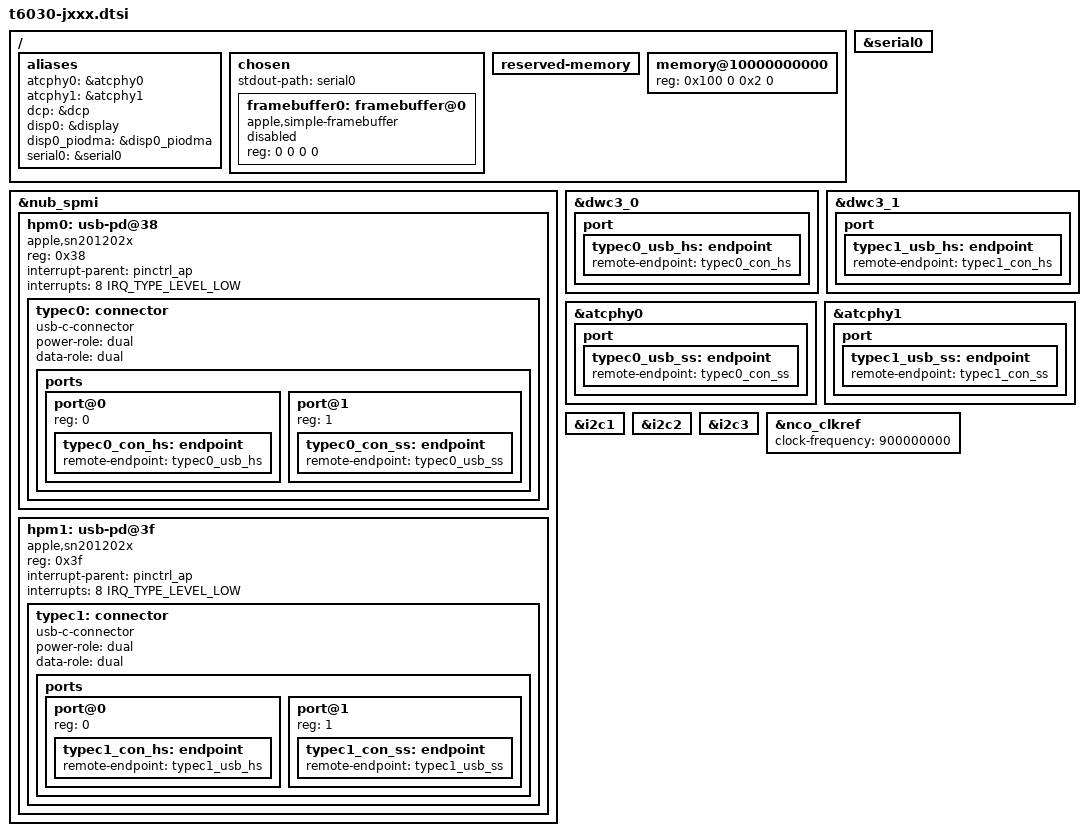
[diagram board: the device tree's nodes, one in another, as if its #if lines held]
// SPDX-License-Identifier: GPL-2.0+ OR MIT
/*
 * Apple M3 MacBook Pro (M3, 2023)
 *
 * This file contains parts common to all Apple M3 devices using the t6030 SoC.
 *
 * target-type: J514 ,..
 *
 * Copyright The Asahi Linux Contributors
 */

/ {
	aliases {
#ifdef T6030_BRINGUP_UNKNOWN
		atcphy0 = &atcphy0;
		atcphy1 = &atcphy1;
		dcp = &dcp;
		disp0 = &display;
		disp0_piodma = &disp0_piodma;
#endif // T6030_BRINGUP_UNKNOWN
		serial0 = &serial0;
	};

	chosen {
		#address-cells = <2>;
		#size-cells = <2>;
		ranges;

		stdout-path = "serial0";

		framebuffer0: framebuffer@0 {
			compatible = "apple,simple-framebuffer", "simple-framebuffer";
			reg = <0 0 0 0>; /* To be filled by loader */
			//power-domains = <&ps_disp_cpu>;
			/* Format properties will be added by loader */
			status = "disabled";
		};
	};

	reserved-memory {
		#address-cells = <2>;
		#size-cells = <2>;
		ranges;
		/* To be filled by loader */
	};

	memory@10000000000 {
		device_type = "memory";
		reg = <0x100 0 0x2 0>; /* To be filled by loader */
	};

};

&serial0 {
	status = "okay";
};

#ifdef T6030_BRINGUP_UNKNOWN
//left-back
&nub_spmi {
	status = "okay";

	hpm0: usb-pd@38 {
		compatible = "apple,sn201202x";
		reg = <0x38>;
		interrupt-parent = <&pinctrl_ap>;
		interrupts = <8 IRQ_TYPE_LEVEL_LOW>;
		interrupt-names = "irq";

		typec0: connector {
			compatible = "usb-c-connector";
			power-role = "dual";
			data-role = "dual";

			ports {
				#address-cells = <1>;
				#size-cells = <0>;
				port@0 {
					reg = <0>;
					typec0_con_hs: endpoint {
						remote-endpoint = <&typec0_usb_hs>;
					};
				};
				port@1 {
					reg = <1>;
					typec0_con_ss: endpoint {
						remote-endpoint = <&typec0_usb_ss>;
					};
				};
			};
		};
	};
//left-front
	hpm1: usb-pd@3f {
		compatible = "apple,sn201202x";
		reg = <0x3f>;
		interrupt-parent = <&pinctrl_ap>;
		interrupts = <8 IRQ_TYPE_LEVEL_LOW>;
		interrupt-names = "irq";

		typec1: connector {
			compatible = "usb-c-connector";
			power-role = "dual";
			data-role = "dual";

			ports {
				#address-cells = <1>;
				#size-cells = <0>;
				port@0 {
					reg = <0>;
					typec1_con_hs: endpoint {
						remote-endpoint = <&typec1_usb_hs>;
					};
				};
				port@1 {
					reg = <1>;
					typec1_con_ss: endpoint {
						remote-endpoint = <&typec1_usb_ss>;
					};
				};
			};
		};
	};
};

/* USB controllers */
&dwc3_0 {
	port {
		typec0_usb_hs: endpoint {
			remote-endpoint = <&typec0_con_hs>;
		};
	};
};

&dwc3_1 {
	port {
		typec1_usb_hs: endpoint {
			remote-endpoint = <&typec1_con_hs>;
		};
	};
};

/* Type-C PHYs */
&atcphy0 {
	port {
		typec0_usb_ss: endpoint {
			remote-endpoint = <&typec0_con_ss>;
		};
	};
};

&atcphy1 {
	port {
		typec1_usb_ss: endpoint {
			remote-endpoint = <&typec1_con_ss>;
		};
	};
};


&i2c1 {
	status = "okay";
};

&i2c2 {
	status = "okay";
};

&i2c3 {
	status = "okay";
};

&nco_clkref {
	clock-frequency = <900000000>;
};

#include "spi1-nvram.dtsi"
#endif // T6030_BRINGUP_UNKNOWN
